# BAT32G157 register map
Vendor: Cmsemicon; Series: BAT32G157; File version: 1.0
CPU: CM0+ r0p1, little endian, no MPU, no FPU, VTOR, 2 interrupt priority bits
Registers are 8-bit, read-write, reset 0x0 unless marked. A register's access mark holds for its fields unless they carry their own. Offsets are from the block's base; [hi:lo] are bit positions.

## SPIHS0 — Serial Interface SPI0
Base 0x40042400
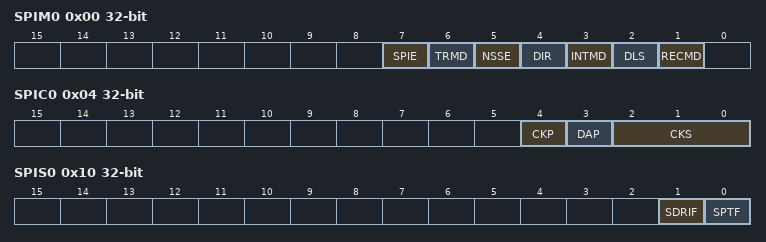
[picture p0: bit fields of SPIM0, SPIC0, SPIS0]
0x00 SPIM0 32-bit — SPI mode control register
  [7] SPIE — SPI operation enable
  [6] TRMD — Transfer and Receive mode
  [5] NSSE — NSS pin enable
  [4] DIR — MSB of LSB mode select
  [3] INTMD — interrupt source select
  [2] DLS — data length control
  [1] RECMD — Receive mode selection
0x04 SPIC0 32-bit — SPI control register
  [4] CKP — Selection of clock phase for SPI
  [3] DAP — Selection of data phase for SPI
  [2:0] CKS — Operation clock control
0x08 SDRO0 32-bit (reset mask 0xFFFF) — Data buffer of transmission
0x0C SDRI0 32-bit (reset mask 0xFFFF) — Data buffer of reception
0x10 SPIS0 32-bit — SPI status register
  [1] SDRIF — Receive buffer non-empty flag
  [0] SPTF — SPI transmission status flag

## SPIHS1 — Serial Interface SPI1
Base 0x40042800
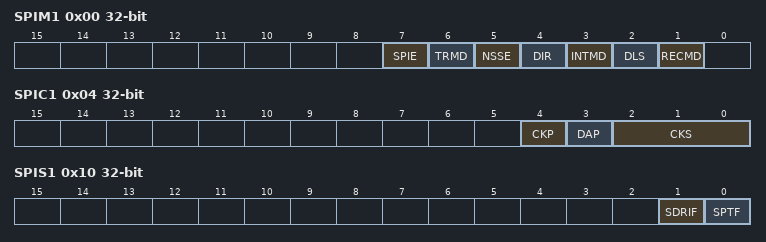
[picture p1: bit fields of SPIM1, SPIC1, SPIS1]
0x00 SPIM1 32-bit — SPI mode control register
  [7] SPIE — SPI operation enable
  [6] TRMD — Transfer and Receive mode
  [5] NSSE — NSS pin enable
  [4] DIR — MSB of LSB mode select
  [3] INTMD — interrupt source select
  [2] DLS — data length control
  [1] RECMD — Receive mode selection
0x04 SPIC1 32-bit — SPI control register
  [4] CKP — Selection of clock phase for SPI
  [3] DAP — Selection of data phase for SPI
  [2:0] CKS — Operation clock control
0x08 SDRO1 32-bit (reset mask 0xFFFF) — Data buffer of transmission
0x0C SDRI1 32-bit (reset mask 0xFFFF) — Data buffer of reception
0x10 SPIS1 32-bit — SPI status register
  [1] SDRIF — Receive buffer non-empty flag
  [0] SPTF — SPI transmission status flag

## IICA0 — Serial Interface I2C with multimaster and wakeup supported
Base 0x40041A30
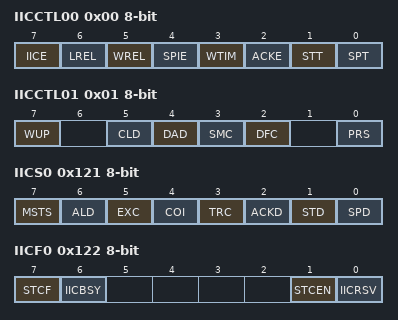
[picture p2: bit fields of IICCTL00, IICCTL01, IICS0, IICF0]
0x00 IICCTL00 — IICA0 control register 0
  [7] IICE — I2C operation enable
  [6] LREL — Exit from communications
  [5] WREL — Wait cancellation
  [4] SPIE — Enable generation of interrupt request when stop condition is detected
  [3] WTIM — Control of wait and interrupt request generation
  [2] ACKE — Acknowledgment control
  [1] STT — Start condition trigger
  [0] SPT — Stop condition trigger
0x01 IICCTL01 — IICA0 control register 1
  [7] WUP — Control of address match wakeup
  [5] CLD ro — Detection of SCLAn pin level (valid only when IICEn = 1)
  [4] DAD ro — Detection of SDAAn pin level (valid only when IICEn = 1)
  [3] SMC — Operation mode switching
  [2] DFC — Digital filter operation control
  [0] PRS — Operation clock (fMCK) contro
0x02 IICWL0 reset 0xFF — IICA0 low-level width setting register
0x03 IICWH0 reset 0xFF — IICA0 high-level width setting register
0x04 SVA0 (reset mask 0xFE) — Slave address register
0x120 IICA0 — IICA0 shift register
0x121 IICS0 ro — IICA0 status register
  [7] MSTS — Master status check flag
  [6] ALD — Detection of arbitration loss
  [5] EXC — Detection of extension code reception
  [4] COI — Detection of matching addresses
  [3] TRC — Detection of transmit/receive status
  [2] ACKD — Detection of acknowledge (ACK)
  [1] STD — Detection of start condition
  [0] SPD — Detection of stop condition
0x122 IICF0 — IICA0 flag register
  [7] STCF ro — STT clear flag
  [6] IICBSY ro — I2C bus status flag
  [1] STCEN — Initial start enable trigger
  [0] IICRSV — Communication reservation function disable bit

## IICA1 — Serial Interface I2C with multimaster and wakeup supported
Base 0x40042E30
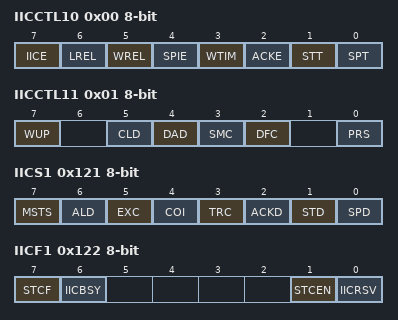
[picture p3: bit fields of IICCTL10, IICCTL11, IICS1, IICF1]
0x00 IICCTL10 — IICA1 control register 0
  [7] IICE — I2C operation enable
  [6] LREL — Exit from communications
  [5] WREL — Wait cancellation
  [4] SPIE — Enable generation of interrupt request when stop condition is detected
  [3] WTIM — Control of wait and interrupt request generation
  [2] ACKE — Acknowledgment control
  [1] STT — Start condition trigger
  [0] SPT — Stop condition trigger
0x01 IICCTL11 — IICA1 control register 1
  [7] WUP — Control of address match wakeup
  [5] CLD ro — Detection of SCLAn pin level (valid only when IICEn = 1)
  [4] DAD ro — Detection of SDAAn pin level (valid only when IICEn = 1)
  [3] SMC — Operation mode switching
  [2] DFC — Digital filter operation control
  [0] PRS — Operation clock (fMCK) contro
0x02 IICWL1 reset 0xFF — IICA1 low-level width setting register
0x03 IICWH1 reset 0xFF — IICA1 high-level width setting register
0x04 SVA1 (reset mask 0xFE) — Slave address register
0x120 IICA1 — IICA1 shift register
0x121 IICS1 ro — IICA1 status register
  [7] MSTS — Master status check flag
  [6] ALD — Detection of arbitration loss
  [5] EXC — Detection of extension code reception
  [4] COI — Detection of matching addresses
  [3] TRC — Detection of transmit/receive status
  [2] ACKD — Detection of acknowledge (ACK)
  [1] STD — Detection of start condition
  [0] SPD — Detection of stop condition
0x122 IICF1 — IICA1 flag register
  [7] STCF ro — STT clear flag
  [6] IICBSY ro — I2C bus status flag
  [1] STCEN — Initial start enable trigger
  [0] IICRSV — Communication reservation function disable bit
